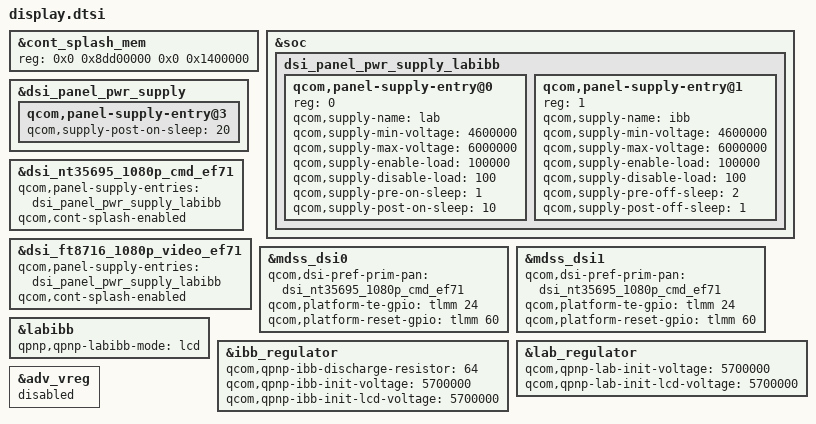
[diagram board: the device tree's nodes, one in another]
// SPDX-License-Identifier: GPL-2.0-only

#include "panel/dsi-panel-nt35695-1080p-cmd-ef71.dtsi"
#include "panel/dsi-panel-nt35695-1080p-video-ef71.dtsi"
#include "panel/dsi-panel-ft8716-1080p-video-ef71.dtsi"

/*
 * The Pantech bootloader draws its splash at 0x8dd00000. With the generic
 * 0x90000000 the kernel takes over a blank buffer, which the FT8716 video
 * mode panel shows as white.
 */
&cont_splash_mem {
	reg = <0x0 0x8dd00000 0x0 0x1400000>;
};

&soc {
	/* Both panels are powered from LAB/IBB only */
	dsi_panel_pwr_supply_labibb: dsi_panel_pwr_supply_labibb {
		#address-cells = <1>;
		#size-cells = <0>;

		qcom,panel-supply-entry@0 {
			reg = <0>;
			qcom,supply-name = "lab";
			qcom,supply-min-voltage = <4600000>;
			qcom,supply-max-voltage = <6000000>;
			qcom,supply-enable-load = <100000>;
			qcom,supply-disable-load = <100>;
			qcom,supply-pre-on-sleep = <1>;
			qcom,supply-post-on-sleep = <10>;
		};

		qcom,panel-supply-entry@1 {
			reg = <1>;
			qcom,supply-name = "ibb";
			qcom,supply-min-voltage = <4600000>;
			qcom,supply-max-voltage = <6000000>;
			qcom,supply-enable-load = <100000>;
			qcom,supply-disable-load = <100>;
			qcom,supply-pre-off-sleep = <2>;
			qcom,supply-post-off-sleep = <1>;
		};
	};
};

&dsi_panel_pwr_supply {
	/delete-node/ qcom,panel-supply-entry@1;

	qcom,panel-supply-entry@3 {
		qcom,supply-post-on-sleep = <20>;
	};
};

&dsi_nt35695_1080p_cmd_ef71 {
	qcom,panel-supply-entries = <&dsi_panel_pwr_supply_labibb>;
	qcom,cont-splash-enabled;
};

&dsi_ft8716_1080p_video_ef71 {
	qcom,panel-supply-entries = <&dsi_panel_pwr_supply_labibb>;
	qcom,cont-splash-enabled;
};

&mdss_dsi0 {
	qcom,dsi-pref-prim-pan = <&dsi_nt35695_1080p_cmd_ef71>;
	qcom,platform-te-gpio = <&tlmm 24 0>;
	qcom,platform-reset-gpio = <&tlmm 60 0>;
	/delete-property/ qcom,platform-bklight-en-gpio;
};

&mdss_dsi1 {
	qcom,dsi-pref-prim-pan = <&dsi_nt35695_1080p_cmd_ef71>;
	qcom,platform-te-gpio = <&tlmm 24 0>;
	qcom,platform-reset-gpio = <&tlmm 60 0>;
	/delete-property/ qcom,platform-bklight-en-gpio;
	/delete-property/ qcom,pluggable;
};

&labibb {
	status = "ok";
	qpnp,qpnp-labibb-mode = "lcd";
};

&ibb_regulator {
	qcom,qpnp-ibb-discharge-resistor = <64>;	/* 47 nF in LCD mode */
	qcom,qpnp-ibb-init-voltage = <5700000>;
	qcom,qpnp-ibb-init-lcd-voltage = <5700000>;
};

&lab_regulator {
	qcom,qpnp-lab-init-voltage = <5700000>;
	qcom,qpnp-lab-init-lcd-voltage = <5700000>;
};

/* The DSI to HDMI bridge regulator is not fitted */
&adv_vreg {
	status = "disabled";
};
